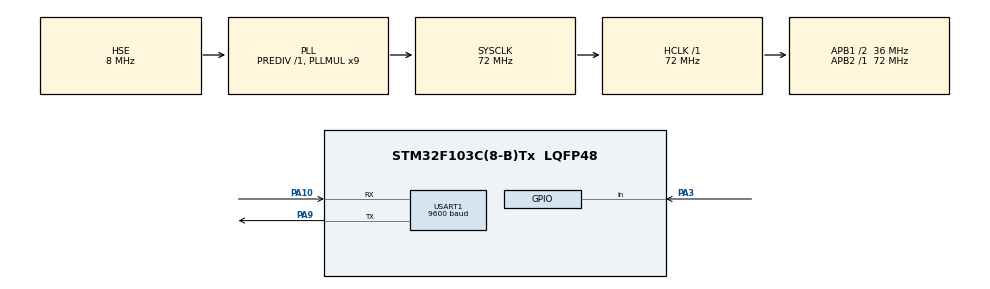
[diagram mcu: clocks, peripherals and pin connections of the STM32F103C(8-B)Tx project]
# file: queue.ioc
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Mcu.Family=STM32F1
Mcu.Name=STM32F103C(8-B)Tx
Mcu.Package=LQFP48
NVIC.PriorityGroup=NVIC_PRIORITYGROUP_4
NVIC.TIM4_IRQn=true\:15\:0\:true\:false\:true\:false\:true\:true
NVIC.TimeBase=TIM4_IRQn
NVIC.TimeBaseIP=TIM4
PA10.Mode=Asynchronous
PA10.Signal=USART1_RX
PA13.Mode=Serial_Wire
PA13.Signal=SYS_JTMS-SWDIO
PA14.Mode=Serial_Wire
PA14.Signal=SYS_JTCK-SWCLK
PA3.GPIO_PuPd=GPIO_PULLDOWN
PA3.Signal=GPIO_Input
PA9.Mode=Asynchronous
PA9.Signal=USART1_TX
PC14-OSC32_IN.Mode=LSE-External-Oscillator
PC14-OSC32_IN.Signal=RCC_OSC32_IN
PC15-OSC32_OUT.Mode=LSE-External-Oscillator
PC15-OSC32_OUT.Signal=RCC_OSC32_OUT
PD0-OSC_IN.Mode=HSE-External-Oscillator
PD0-OSC_IN.Signal=RCC_OSC_IN
PD1-OSC_OUT.Mode=HSE-External-Oscillator
PD1-OSC_OUT.Signal=RCC_OSC_OUT
ProjectManager.HeapSize=0x200
ProjectManager.StackSize=0x400
ProjectManager.TargetToolchain=CMake
RCC.AHBFreq_Value=72000000
RCC.APB1CLKDivider=RCC_HCLK_DIV2
RCC.APB1Freq_Value=36000000
RCC.APB1TimFreq_Value=72000000
RCC.APB2Freq_Value=72000000
RCC.APB2TimFreq_Value=72000000
RCC.HCLKFreq_Value=72000000
RCC.PLLMUL=RCC_PLL_MUL9
RCC.PLLSourceVirtual=RCC_PLLSOURCE_HSE
RCC.SYSCLKFreq_VALUE=72000000
RCC.SYSCLKSource=RCC_SYSCLKSOURCE_PLLCLK
RCC.USBFreq_Value=72000000
USART1.BaudRate=9600
USART1.VirtualMode=VM_ASYNC
VP_SYS_VS_tim4.Mode=TIM4
board=custom

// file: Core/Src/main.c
/* USER CODE BEGIN Header */
/**
  ******************************************************************************
  * @file           : main.c
  * @brief          : Main program body
  ******************************************************************************
  * @attention
  *
  * Copyright (c) 2026 STMicroelectronics.
  * All rights reserved.
  *
  * This software is licensed under terms that can be found in the LICENSE file
  * in the root directory of this software component.
  * If no LICENSE file comes with this software, it is provided AS-IS.
  *
  ******************************************************************************
  */
/* USER CODE END Header */
#include "main.h"
#include "usart.h"
#include "gpio.h"

/* USER CODE BEGIN Includes */
#include "FreeRTOS.h"
#include "portmacro.h"
#include "projdefs.h"
#include "stm32f103xb.h"
#include "stm32f1xx_hal.h"
#include "stm32f1xx_hal_gpio.h"
#include "task.h"
#include <stdio.h>
#include <string.h>
#include "queue.h"
/* USER CODE END Includes */

/* USER CODE BEGIN PV */
TaskHandle_t task1_handle = NULL;
TaskHandle_t task2_handle = NULL;
TaskHandle_t start_task_handler = NULL;
QueueHandle_t Queue1Handle;
/* USER CODE END PV */

void SystemClock_Config(void);
/* USER CODE BEGIN PFP */
void FreeRTOS_Start(void);
void Start_Task(void *pvParameters);
void Task1(void *argument);
void Task2(void *argument);
/* USER CODE END PFP */

int main(void)
{

  /* MCU Configuration--------------------------------------------------------*/

  /* Reset of all peripherals, Initializes the Flash interface and the Systick. */
  HAL_Init();

  /* Configure the system clock */
  SystemClock_Config();

  /* Initialize all configured peripherals */
  MX_GPIO_Init();
  MX_USART1_UART_Init();
  /* USER CODE BEGIN 2 */

  Queue1Handle = xQueueCreate(5, sizeof(uint32_t));
  if (Queue1Handle == NULL)
  {
    printf("Create Queue Fail\r\n");
  }

  FreeRTOS_Start();

  /* USER CODE END 2 */

  /* Infinite loop */
  while (1)
  {

  }
}

void SystemClock_Config(void)
{
  RCC_OscInitTypeDef RCC_OscInitStruct = {0};
  RCC_ClkInitTypeDef RCC_ClkInitStruct = {0};

  /** Initializes the RCC Oscillators according to the specified parameters
  * in the RCC_OscInitTypeDef structure.
  */
  RCC_OscInitStruct.OscillatorType = RCC_OSCILLATORTYPE_HSE;
  RCC_OscInitStruct.HSEState = RCC_HSE_ON;
  RCC_OscInitStruct.HSEPredivValue = RCC_HSE_PREDIV_DIV1;
  RCC_OscInitStruct.HSIState = RCC_HSI_ON;
  RCC_OscInitStruct.PLL.PLLState = RCC_PLL_ON;
  RCC_OscInitStruct.PLL.PLLSource = RCC_PLLSOURCE_HSE;
  RCC_OscInitStruct.PLL.PLLMUL = RCC_PLL_MUL9;
  if (HAL_RCC_OscConfig(&RCC_OscInitStruct) != HAL_OK)
  {
    Error_Handler();
  }

  /** Initializes the CPU, AHB and APB buses clocks
  */
  RCC_ClkInitStruct.ClockType = RCC_CLOCKTYPE_HCLK|RCC_CLOCKTYPE_SYSCLK
                              |RCC_CLOCKTYPE_PCLK1|RCC_CLOCKTYPE_PCLK2;
  RCC_ClkInitStruct.SYSCLKSource = RCC_SYSCLKSOURCE_PLLCLK;
  RCC_ClkInitStruct.AHBCLKDivider = RCC_SYSCLK_DIV1;
  RCC_ClkInitStruct.APB1CLKDivider = RCC_HCLK_DIV2;
  RCC_ClkInitStruct.APB2CLKDivider = RCC_HCLK_DIV1;

  if (HAL_RCC_ClockConfig(&RCC_ClkInitStruct, FLASH_LATENCY_2) != HAL_OK)
  {
    Error_Handler();
  }
}

/* USER CODE BEGIN 4 */
int __io_putchar(int ch)
{
  uint8_t data = (uint8_t)ch;
  HAL_UART_Transmit(&huart1, &data, 1, HAL_MAX_DELAY);
  return ch;
}

void FreeRTOS_Start(void)
{
  xTaskCreate(Start_Task, "Start_Task", 256, NULL, 1, &start_task_handler);
  vTaskStartScheduler();
}

void Start_Task(void * pvParameters)
{
  taskENTER_CRITICAL();               /* 進入臨界區 */

  xTaskCreate(Task1, "Task1", 128, NULL, 2, &task1_handle);
  xTaskCreate(Task2, "Task2", 128, NULL, 3, &task2_handle);

  vTaskDelete(NULL);
  taskEXIT_CRITICAL();                /* 退出臨界區 */
}

// 當按下 key，將值寫入 Queue
void Task1(void *argument)
{
  uint32_t TxData = 537;
  BaseType_t result;

  for (;;)
  {
    if (HAL_GPIO_ReadPin(GPIOA, GPIO_PIN_3) == GPIO_PIN_SET)
    {
      vTaskDelay(pdMS_TO_TICKS(20));
      if (HAL_GPIO_ReadPin(GPIOA, GPIO_PIN_3) == GPIO_PIN_SET)
      {
        result = xQueueSend(Queue1Handle, &TxData, portMAX_DELAY);
        if (result == pdPASS)
        {
          printf("Send Success\r\n");
        }
        else
        {
          printf("Send Fail\r\n");
        }
        while (HAL_GPIO_ReadPin(GPIOA, GPIO_PIN_3) == GPIO_PIN_SET)
        {
          vTaskDelay(pdMS_TO_TICKS(10));
        }
      }
      vTaskDelay(pdMS_TO_TICKS(20));
    }
    vTaskDelay(pdMS_TO_TICKS(50));
  }
}

// 讀取 Queue 的訊息，印出收到的值
void Task2(void *argument)
{
  uint32_t RxData;

  for (;;)
  {
    xQueueReceive(Queue1Handle, &RxData, portMAX_DELAY);
    printf("Receive: %ld\r\n", RxData);
    vTaskDelay(pdMS_TO_TICKS(50));
  }
}

/* USER CODE END 4 */

void HAL_TIM_PeriodElapsedCallback(TIM_HandleTypeDef *htim)
{
  if (htim->Instance == TIM4)
  {
    HAL_IncTick();
  }
}

void Error_Handler(void)
{
  __disable_irq();
  while (1)
  {
  }
}
